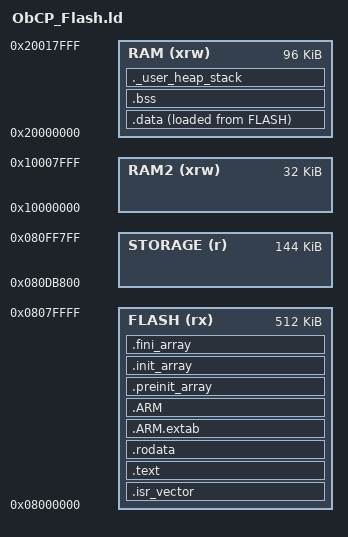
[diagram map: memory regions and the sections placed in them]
/*
******************************************************************************
**
** @file        : LinkerScript.ld
**
** @author      : Auto-generated by STM32CubeIDE
**
**  Abstract    : Linker script for NUCLEO-L476RG Board embedding STM32L476RGTx Device from stm32l4 series
**                      1024Kbytes FLASH
**                      96Kbytes RAM
**                      32Kbytes RAM2
**
**                Set heap size, stack size and stack location according
**                to application requirements.
**
**                Set memory bank area and size if external memory is used
**
**  Target      : STMicroelectronics STM32
**
**  Distribution: The file is distributed as is, without any warranty
**                of any kind.
**
******************************************************************************
** @attention
**
** Copyright (c) 2022 STMicroelectronics.
** All rights reserved.
**
** This software is licensed under terms that can be found in the LICENSE file
** in the root directory of this software component.
** If no LICENSE file comes with this software, it is provided AS-IS.
**
******************************************************************************
*/

/* Lecture pédagogique du script GNU ld.
 * Les adresses et tailles sont exprimées en octets ; K signifie 1 024 octets.
 * MEMORY définit les régions disponibles. SECTIONS y place code, constantes et RAM.
 * Le programme occupe au plus la banque 1. STORAGE nomme une réserve physique,
 * sans y placer de section initialisée : un HEX ne doit jamais effacer les dessins.
 * .data est stockée en flash puis copiée en RAM par Reset_Handler.
 * .bss est mise à zéro au reset. .rodata reste en flash, donc ne consomme pas de RAM.
 * La pile dispose d’une réservation de 4 Kio et le tas de 1 Kio. App n’utilise pas
 * d’allocation dynamique. La mesure de pile maximale se fait sur la cible.
 */
/* Entry Point */
ENTRY(Reset_Handler)

/* Highest address of the user mode stack */
_estack = ORIGIN(RAM) + LENGTH(RAM); /* end of "RAM" Ram type memory */

_Min_Heap_Size = 0x400; /* required amount of heap */
_Min_Stack_Size = 0x1000; /* required amount of stack */

/* Memories definition */
MEMORY
{
  RAM    (xrw)    : ORIGIN = 0x20000000,   LENGTH = 96K
  RAM2    (xrw)    : ORIGIN = 0x10000000,   LENGTH = 32K
  FLASH    (rx)    : ORIGIN = 0x08000000,  LENGTH = 512K
  /* Deux pages de réactivité précèdent les axes 0.3 et les données 0.2.
     La dernière page du démonstrateur Wi-Fi est distincte. */
  STORAGE  (r)     : ORIGIN = 0x080DB800,  LENGTH = 144K
}

/* Ces symboles sont des adresses. flash_port.c en contrôle la géométrie avant d’autoriser les écritures. */
__obcp_storage_start = ORIGIN(STORAGE);
__obcp_storage_end = ORIGIN(STORAGE) + LENGTH(STORAGE);
ASSERT((__obcp_storage_start % 2048) == 0, "Pages flash non alignees")
ASSERT(__obcp_storage_start + 4096 == 0x080DC800, "Axes des jeux 0.3.0 deplaces")
ASSERT(__obcp_storage_start + 8192 == 0x080DD800, "Calibrage tactile 0.2.0 deplace")
ASSERT(__obcp_storage_start + 12288 == 0x080DE800, "Emplacements 0.1.1 deplaces")
ASSERT(__obcp_storage_end == 0x080FF800, "Geometrie stockage incorrecte")

/* Sections */
SECTIONS
{
  /* The startup code into "FLASH" Rom type memory */
  .isr_vector :
  {
    . = ALIGN(4);
    KEEP(*(.isr_vector)) /* Startup code */
    . = ALIGN(4);
  } >FLASH

  /* The program code and other data into "FLASH" Rom type memory */
  .text :
  {
    . = ALIGN(4);
    *(.text)           /* .text sections (code) */
    *(.text*)          /* .text* sections (code) */
    *(.glue_7)         /* glue arm to thumb code */
    *(.glue_7t)        /* glue thumb to arm code */
    *(.eh_frame)

    KEEP (*(.init))
    KEEP (*(.fini))

    . = ALIGN(4);
    _etext = .;        /* define a global symbols at end of code */
  } >FLASH

  /* Constant data into "FLASH" Rom type memory */
  .rodata :
  {
    . = ALIGN(4);
    *(.rodata)         /* .rodata sections (constants, strings, etc.) */
    *(.rodata*)        /* .rodata* sections (constants, strings, etc.) */
    . = ALIGN(4);
  } >FLASH

  .ARM.extab   : {
    . = ALIGN(4);
    *(.ARM.extab* .gnu.linkonce.armextab.*)
    . = ALIGN(4);
  } >FLASH

  .ARM : {
    . = ALIGN(4);
    __exidx_start = .;
    *(.ARM.exidx*)
    __exidx_end = .;
    . = ALIGN(4);
  } >FLASH

  .preinit_array     :
  {
    . = ALIGN(4);
    PROVIDE_HIDDEN (__preinit_array_start = .);
    KEEP (*(.preinit_array*))
    PROVIDE_HIDDEN (__preinit_array_end = .);
    . = ALIGN(4);
  } >FLASH

  .init_array :
  {
    . = ALIGN(4);
    PROVIDE_HIDDEN (__init_array_start = .);
    KEEP (*(SORT(.init_array.*)))
    KEEP (*(.init_array*))
    PROVIDE_HIDDEN (__init_array_end = .);
    . = ALIGN(4);
  } >FLASH

  .fini_array :
  {
    . = ALIGN(4);
    PROVIDE_HIDDEN (__fini_array_start = .);
    KEEP (*(SORT(.fini_array.*)))
    KEEP (*(.fini_array*))
    PROVIDE_HIDDEN (__fini_array_end = .);
    . = ALIGN(4);
  } >FLASH

  /* Used by the startup to initialize data */
  _sidata = LOADADDR(.data);

  /* Initialized data sections into "RAM" Ram type memory */
  .data :
  {
    . = ALIGN(4);
    _sdata = .;        /* create a global symbol at data start */
    *(.data)           /* .data sections */
    *(.data*)          /* .data* sections */
    *(.RamFunc)        /* .RamFunc sections */
    *(.RamFunc*)       /* .RamFunc* sections */

    . = ALIGN(4);
    _edata = .;        /* define a global symbol at data end */

  } >RAM AT> FLASH

  /* Uninitialized data section into "RAM" Ram type memory */
  . = ALIGN(4);
  .bss :
  {
    /* This is used by the startup in order to initialize the .bss section */
    _sbss = .;         /* define a global symbol at bss start */
    __bss_start__ = _sbss;
    *(.bss)
    *(.bss*)
    *(COMMON)

    . = ALIGN(4);
    _ebss = .;         /* define a global symbol at bss end */
    __bss_end__ = _ebss;
  } >RAM

  /* User_heap_stack section, used to check that there is enough "RAM" Ram  type memory left */
  ._user_heap_stack :
  {
    . = ALIGN(8);
    PROVIDE ( end = . );
    PROVIDE ( _end = . );
    . = . + _Min_Heap_Size;
    . = . + _Min_Stack_Size;
    . = ALIGN(8);
  } >RAM

  /* Remove information from the compiler libraries */
  /DISCARD/ :
  {
    libc.a ( * )
    libm.a ( * )
    libgcc.a ( * )
  }

  .ARM.attributes 0 : { *(.ARM.attributes) }
}
